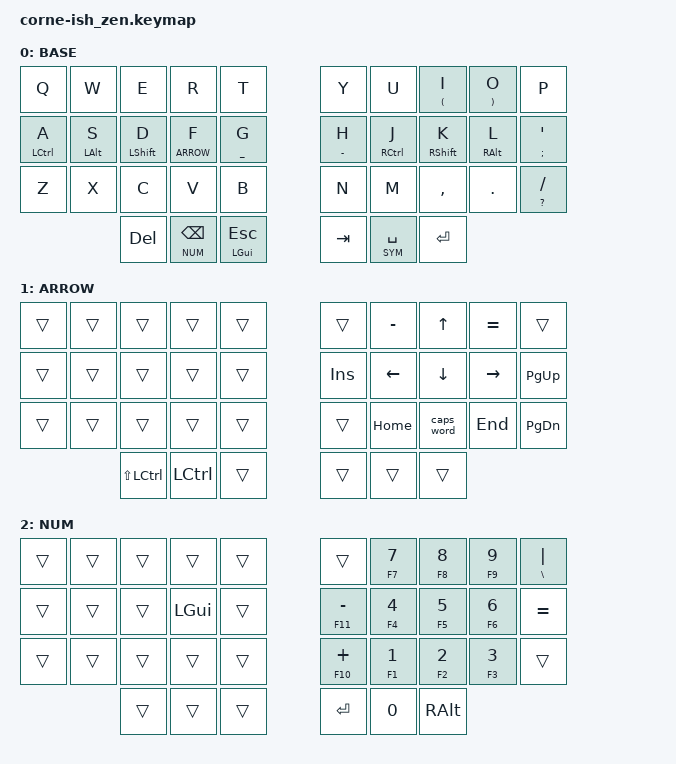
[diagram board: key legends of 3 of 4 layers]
/*
 *
 * Copyright (c) 2021 Darryl deHaan
 * SPDX-License-Identifier: MIT
 *
 */

 #include <behaviors.dtsi>
 #include <dt-bindings/zmk/keys.h>
 #include <dt-bindings/zmk/bt.h>

#define BASE 0
#define ARROW   1
#define NUM  2
#define SYM 3

 / {
   chosen {
     //zmk,matrix_transform = &default_transform;
     zmk,matrix_transform = &five_column_transform;
   };
 };


 &mt {
     tapping-term-ms = <150>;
 };

 / {

 behaviors {
     hm: homerow_mods {
         compatible = "zmk,behavior-hold-tap";
         label = "HOMEROW_MODS";
         #binding-cells = <2>;
         tapping-term-ms = <150>;
         quick-tap-ms = <0>;
         flavor = "tap-preferred";
         bindings = <&kp>, <&kp>;
     };
 };

         keymap {
                 compatible = "zmk,keymap";

                 default_layer {
                         label = "BASE";
                         
                         bindings = <
    &kp Q &kp W &kp E &kp R &kp T &kp Y &kp U  &hm LPAR I &hm RPAR O   &kp P
    &hm LCTRL A &hm LALT S &hm LSHIFT D &lt ARROW F &hm UNDER G &hm MINUS H &hm RCTRL J &hm RSHIFT K &hm RALT L &hm SEMI SQT 
    &kp Z &kp X &kp C &kp V &kp B  &kp N &kp M &kp COMMA &kp DOT &hm QMARK  FSLH 
       &kp DEL &lt NUM BACKSPACE &hm LGUI ESC  &kp TAB &lt SYM SPACE &kp  RET
       
                         >;
                 };
                 nav_layer {
                         label = "ARROW";

                         bindings = <
   &trans &trans &trans &trans &trans &trans &kp MINUS &kp UP &kp EQUAL &trans
   &trans &trans &trans &trans &trans &kp INSERT &kp LEFT &kp DOWN &kp RIGHT &kp PG_UP
   &trans &trans &trans &trans &trans &trans &kp HOME &caps_word &kp END &kp PG_DN
                           	   &kp LS(LCTRL) &kp LCTRL &trans &trans &trans &trans
                         >;
                 };

                numbers_layer {
                         label = "NUM";

                         bindings = <
   &trans &trans &trans &trans &trans &trans &hm F7 N7  &hm F8 N8 &hm F9 N9 &hm BSLH PIPE 
   &trans &trans &trans &kp LGUI &trans &hm F11 MINUS &hm F4 N4 &hm F5 N5 &hm F6 N6 &kp EQUAL 
   &trans &trans &trans &trans &trans &hm F10 PLUS &hm F1 N1  &hm F2 N2 &hm F3 N3 &trans 
                 &trans &trans &trans &kp RET &kp N0 &kp RALT
                         >;
                 };
                 symbols_layer {
                         label = "SYM";

                         bindings = <
   &kp EXCL &kp AT &kp HASH &kp DLLR &kp PRCNT &hm TILDE GRAVE &hm F7 N7 &hm F8 N8 &hm F9 N9 &hm BSLH PIPE
  &trans &trans &trans &hm RBRC LBRC &kp UNDER &trans &trans &trans &trans &trans
  &kp  CARET &kp AMPS &kp ASTRK &hm RPAR LPAR &hm RBKT LBKT &trans &trans &trans &trans &trans 
                &trans &trans &trans &trans &trans &trans &trans
                         >;
                 };
         };
 };
